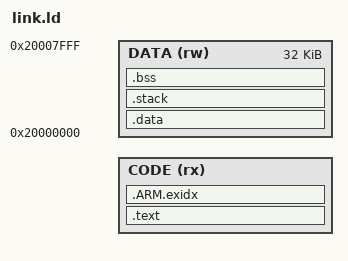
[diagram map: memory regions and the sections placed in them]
/*
 * linker script for GD32C11x with GNU ld
 * BruceOu 2021-12-14
 */

/* Program Entry, set to mark it as "used" and avoid gc */
MEMORY
{
    CODE (rx) : ORIGIN = ROM_ORIGIN, LENGTH = ROM_LENGTH
    DATA (rw) : ORIGIN = 0x20000000, LENGTH =   32k /*  32KB sram */
}
ENTRY(Reset_Handler)
_system_stack_size = 0x200;

SECTIONS
{
    .text :
    {
        . = ALIGN(4);
        _stext = .;
        KEEP(*(.isr_vector))            /* Startup code */
        . = ALIGN(4);
        *(.text)                        /* remaining code */
        *(.text.*)                      /* remaining code */
        *(.rodata)                      /* read-only data (constants) */
        *(.rodata*)
        *(.gnu.linkonce.t*)

        . = ALIGN(4);
        _etext = .;
    } > CODE = 0

    /* .ARM.exidx is sorted, so has to go in its own output section.  */
    __exidx_start = .;
    .ARM.exidx :
    {
        *(.ARM.exidx* .gnu.linkonce.armexidx.*)

        /* This is used by the startup in order to initialize the .data secion */
        _sidata = .;
    } > CODE
    __exidx_end = .;

    /* .data section which is used for initialized data */

    .data : AT (_sidata)
    {
        . = ALIGN(4);
        /* This is used by the startup in order to initialize the .data secion */
        _sdata = . ;

        *(.data)
        *(.data.*)
        *(.gnu.linkonce.d*)

        . = ALIGN(4);
        /* This is used by the startup in order to initialize the .data secion */
        _edata = . ;
    } >DATA

    .stack : 
    {
        . = . + _system_stack_size;
        . = ALIGN(4);
        _estack = .;
    } >DATA

    __bss_start = .;
    .bss :
    {
        . = ALIGN(4);
        /* This is used by the startup in order to initialize the .bss secion */
        _sbss = .;

        *(.bss)
        *(.bss.*)

        . = ALIGN(4);
        /* This is used by the startup in order to initialize the .bss secion */
        _ebss = . ;
        
        *(.bss.init)
    } > DATA
    __bss_end = .;

    _end = .;
}
